# CY8C5868AXI_LP035 register map
File version: 0.1
CY8C58LP
Registers are 8-bit, read-write, no defined reset value unless marked. A register's access mark holds for its fields unless they carry their own. Offsets are from the block's base; lines under a group give offsets from that group; [hi:lo] are bit positions; {n}, {i} and the like mark numbered series; 'fields as' and 'values as' point back to an identical list; <NAME> marks a mode.

## Memory map
0x00000000 UART_1 — UART
0x00000000 UART_2 — UART
0x00000000 UART_3 — UART

## UART_1 — UART
Base 0x00000000
0x40006425 HD_UART_1_RX_ADDRESS1 — RX Address1 Register
0x40006435 HD_UART_1_RX_ADDRESS2 — RX Address2 Register
0x40006445 HD_UART_1_RX_DATA — RX Data Register
0x40006455 HD_UART_1_TX_DATA — TX Data Register
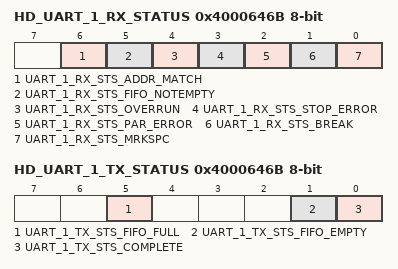
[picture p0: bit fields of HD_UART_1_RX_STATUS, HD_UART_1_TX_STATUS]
0x4000646B HD_UART_1_RX_STATUS — RX status register
  [6] UART_1_RX_STS_ADDR_MATCH ro, [5] UART_1_RX_STS_FIFO_NOTEMPTY ro, [4] UART_1_RX_STS_OVERRUN ro, [3] UART_1_RX_STS_STOP_ERROR ro, [2] UART_1_RX_STS_PAR_ERROR ro, [1] UART_1_RX_STS_BREAK ro, [0] UART_1_RX_STS_MRKSPC ro
0x4000646B HD_UART_1_TX_STATUS — TX status register
  [5] UART_1_TX_STS_FIFO_FULL ro, [1] UART_1_TX_STS_FIFO_EMPTY ro, [0] UART_1_TX_STS_COMPLETE ro

## UART_2 — UART
Base 0x00000000
0x40006527 HD_UART_2_RX_ADDRESS1 — RX Address1 Register
0x40006537 HD_UART_2_RX_ADDRESS2 — RX Address2 Register
0x40006547 HD_UART_2_RX_DATA — RX Data Register
0x40006557 HD_UART_2_TX_DATA — TX Data Register
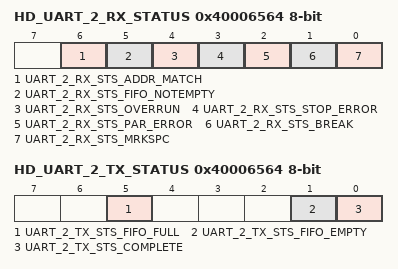
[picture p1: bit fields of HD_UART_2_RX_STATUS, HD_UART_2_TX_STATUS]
0x40006564 HD_UART_2_RX_STATUS — RX status register
  [6] UART_2_RX_STS_ADDR_MATCH ro, [5] UART_2_RX_STS_FIFO_NOTEMPTY ro, [4] UART_2_RX_STS_OVERRUN ro, [3] UART_2_RX_STS_STOP_ERROR ro, [2] UART_2_RX_STS_PAR_ERROR ro, [1] UART_2_RX_STS_BREAK ro, [0] UART_2_RX_STS_MRKSPC ro
0x40006564 HD_UART_2_TX_STATUS — TX status register
  [5] UART_2_TX_STS_FIFO_FULL ro, [1] UART_2_TX_STS_FIFO_EMPTY ro, [0] UART_2_TX_STS_COMPLETE ro

## UART_3 — UART
Base 0x00000000
0x40006424 HD_UART_3_RX_ADDRESS1 — RX Address1 Register
0x40006434 HD_UART_3_RX_ADDRESS2 — RX Address2 Register
0x40006444 HD_UART_3_RX_DATA — RX Data Register
0x40006454 HD_UART_3_TX_DATA — TX Data Register
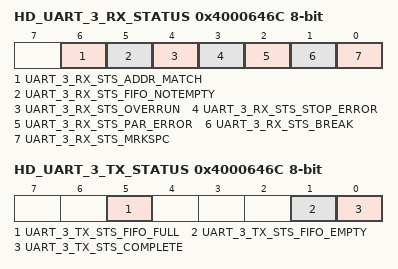
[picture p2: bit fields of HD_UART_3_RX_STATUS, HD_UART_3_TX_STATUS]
0x4000646C HD_UART_3_RX_STATUS — RX status register
  [6] UART_3_RX_STS_ADDR_MATCH ro, [5] UART_3_RX_STS_FIFO_NOTEMPTY ro, [4] UART_3_RX_STS_OVERRUN ro, [3] UART_3_RX_STS_STOP_ERROR ro, [2] UART_3_RX_STS_PAR_ERROR ro, [1] UART_3_RX_STS_BREAK ro, [0] UART_3_RX_STS_MRKSPC ro
0x4000646C HD_UART_3_TX_STATUS — TX status register
  [5] UART_3_TX_STS_FIFO_FULL ro, [1] UART_3_TX_STS_FIFO_EMPTY ro, [0] UART_3_TX_STS_COMPLETE ro
